# iND83213A register map
Vendor: Indiemicro; Series: Rugby; File version: 1.0
CPU: CM0 r0p1, selectable endian, no MPU, no FPU, 4 interrupt priority bits
Registers are 32-bit, read-write, no defined reset value unless marked. A register's access mark holds for its fields unless they carry their own. Offsets are from the block's base; [hi:lo] are bit positions.

## FLASH — FLASH Memory registers
Base 0x50020020; register names take the prefix FLASH_
0x00 FLADDR — Destination address for flash write / erase operation
  [16:0] ADDR — Target address for write/erase operation. In byte writes, this is the read address of the flash to be written to. In erase modes, it is a read address inside the sector to be erased. This register must be written in the correct sequence or the operation will fail.
0x04 FLWRDT — Flash data to be written
  [31:0] DATA — Content to be written into the targeted address. This register must be written in the correct sequence or the operation will fail.
0x08 UNLBWR — Flash data unlock register
  [31:0] UNLOCK_WRITE — Control register to unlock write. A value of 0x55555555 must be written to this address at the correct point in the write sequence or the operation will fail.
0x0C BWRSTRT — Flash write start register
  [31:0] WRITE_START — Control register to start a write. A value of 0xAAAAAAAA must be written to this address at the correct point in the write sequence or the operation will fail.
0x10 UNLSER — Flash sector erase unlock register
  [31:0] UNLOCK_ERASE — Control register to unlock a sector erase. A value of 0x66666666 must be written to this address at the correct point in the sector erase sequence or the operation will fail.
0x14 SERSTRT — Flash sector erase start register
  [31:0] ERASE_START — Control register to commit a sector erase. A value of 0x99999999 must be written to this address at the correct point in the sector erase sequence or the operation will fail.
0x20 FLSCTRL — Flash control register
  [1:0] CTRL — Number of wait states used in the reading process. Each read from flash memory will take number of cycles equal to 1+RWC to complete.
0x24 FLSCP — Flash code protection register
  [31:0] CODE_PROT — Code Protection / SerialWire Lockout Control Code protection control register. Write a value of 0xF2E11047 to disable the SerialWire interface. Write 0x00000000 to enable it. This allows the user program to disable the SerialWire interface to prevent unauthorized debug access to the part. NOTE1: This register does not lock the Flash Memory against read/write/erase by the applications program. Instead what it does is to disable all communications with the debug interface, therefore preventing any external attack. The application code is still able to modify the flash content. NOTE2: Upon Power-On Reset or Normal Reset the system disables the communication for a small time interval (8192 clock cycles). If the application needs to be protected it is mandatory to set this register with the appropriate code in the beginning of the initialization process and before the internal hardware enable the debug communication.
0x30 FLS_UNLOCK_CTRL_OP — Flash Unlock Control Operation Register
  [31:0] UNLOCK_CTRL_OP — Flash Control Operation Register Unlock value. 0xACDC_1972 needs to be written in this register to unlock the Control Operation Register access. When this register is read, it returns the state of the lock: 0: The Control Operation Register is locked. The Control Operation Register (FLASH_CTRL_OP) cannot be written. 1: The Control Operation Register is unlocked. The Control Operation Register (FLASH_CTRL_OP) can be written. Note: After each write to the FLASH_CTRL_OP register, the state of the lock is cleared and the pattern needs to be written again to allow a new configuration of the register.
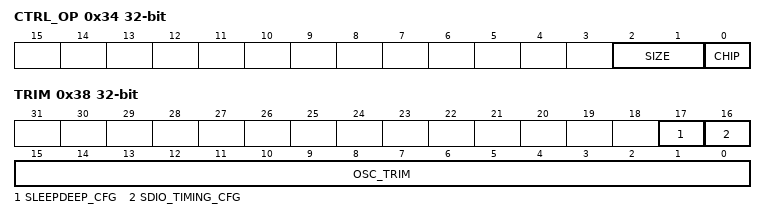
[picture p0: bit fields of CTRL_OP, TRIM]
0x34 CTRL_OP — Flash Control Operation Register
  [2:1] SIZE — SIZE of the write operation. Refer to data sheet for more information of the use of this field.
  [0] CHIP — CHIP bit. This bit is only used during the Erase operation. It allows the system to erase more than one sector. 0: The Erase operation will only erase the sector selected by the FLASH_ADDR register value. 1: The Erase operation will erase the full main array of the flash.
0x38 TRIM — Flash Trim Register
  [17] SLEEPDEEP_CFG — Deep Sleep VDD_IO configuration. This register will be automatically populated with the value stored in the NVR sector 1 (@0001_0000). When set, the system will NOT be reset if VDD_IO is going away during Deep Sleep mode. Otherwise (0), the system is reset if VDD_IO is removed.
  [16] SDIO_TIMING_CFG — SDIO interface timing configuration. This register will be automatically populated with the value stored in the NVR sector 1 (@0001_0000). When set, the SDIO/INT signals are captured on the falling edge of CLK. When cleared, these data are captured on the rising edge of CLK
  [15:0] OSC_TRIM — Oscillator Trim Value. This register will be automatically populated with the value stored in the NVR sector 1 (@0001_0000).
